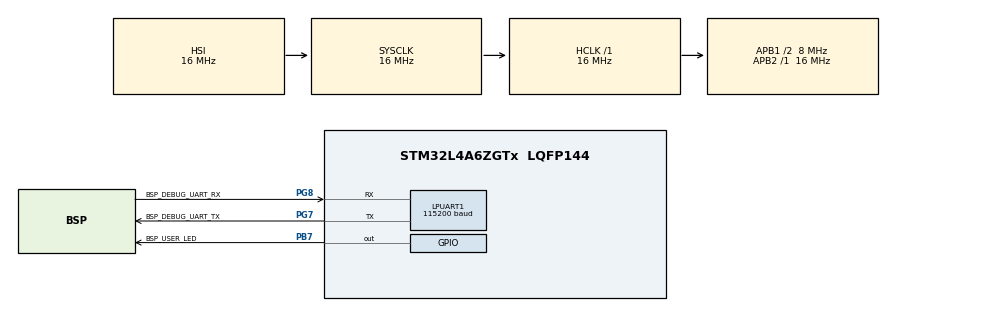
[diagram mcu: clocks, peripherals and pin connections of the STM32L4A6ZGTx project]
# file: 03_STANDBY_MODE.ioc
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LPUART1.BaudRate=115200
LPUART1.WordLength=UART_WORDLENGTH_8B
Mcu.Family=STM32L4
Mcu.Name=STM32L4A6ZGTx
Mcu.Package=LQFP144
NVIC.PriorityGroup=NVIC_PRIORITYGROUP_4
PB7.GPIO_Label=BSP_USER_LED
PB7.Signal=GPIO_Output
PC13.Mode=SYS_WakeUp1
PC13.Signal=SYS_WKUP2
PG7.GPIO_Label=BSP_DEBUG_UART_TX
PG7.Mode=Asynchronous
PG7.Signal=LPUART1_TX
PG8.GPIO_Label=BSP_DEBUG_UART_RX
PG8.Mode=Asynchronous
PG8.Signal=LPUART1_RX
ProjectManager.HeapSize=0x200
ProjectManager.StackSize=0x400
ProjectManager.TargetToolchain=STM32CubeIDE
RCC.ADCFreq_Value=192000000
RCC.AHBFreq_Value=16000000
RCC.APB1CLKDivider=RCC_HCLK_DIV2
RCC.APB1Freq_Value=8000000
RCC.APB1TimFreq_Value=16000000
RCC.APB2Freq_Value=16000000
RCC.APB2TimFreq_Value=16000000
RCC.CortexFreq_Value=16000000
RCC.HCLKFreq_Value=16000000
RCC.HSE_VALUE=8000000
RCC.HSI48_VALUE=48000000
RCC.HSI_VALUE=16000000
RCC.LSE_VALUE=32768
RCC.MSIClockRange=RCC_MSIRANGE_11
RCC.MSI_VALUE=48000000
RCC.SYSCLKFreq_VALUE=16000000
RCC.SYSCLKSource=RCC_SYSCLKSOURCE_HSI
RCC.USBFreq_Value=192000000
RCC.VCOOutputFreq_Value=384000000
board=NUCLEO-L4A6ZG

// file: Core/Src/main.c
/* USER CODE BEGIN Header */
/**
  ******************************************************************************
  * @file           : main.c
  * @brief          : Main program body
  ******************************************************************************
  * @attention
  *
  * Copyright (c) 2024 STMicroelectronics.
  * All rights reserved.
  *
  * This software is licensed under terms that can be found in the LICENSE file
  * in the root directory of this software component.
  * If no LICENSE file comes with this software, it is provided AS-IS.
  *
  ******************************************************************************
  */
/* USER CODE END Header */
#include "main.h"

/* USER CODE BEGIN Includes */
#include "stdio.h"
/* USER CODE END Includes */

UART_HandleTypeDef hlpuart1;

void SystemClock_Config(void);
static void MX_GPIO_Init(void);
static void MX_LPUART1_UART_Init(void);

int main(void)
{

  /* MCU Configuration--------------------------------------------------------*/

  /* Reset of all peripherals, Initializes the Flash interface and the Systick. */
  HAL_Init();

  /* Configure the system clock */
  SystemClock_Config();

  /* Initialize all configured peripherals */
  MX_GPIO_Init();
  MX_LPUART1_UART_Init();
  /* USER CODE BEGIN 2 */

  /*** chek if the sb flag is set ***/
	if (__HAL_PWR_GET_FLAG(PWR_FLAG_SB) != RESET)
	{
		__HAL_PWR_CLEAR_FLAG(PWR_FLAG_SB);		//clear the flag

		/*** display the string ***/
		printf("Wake up from Standby Mode\r\n");

		/*** blink the led ***/
		for (int i = 0; i < 20; i++)
		{
			HAL_GPIO_TogglePin(BSP_USER_LED_GPIO_Port, BSP_USER_LED_Pin);
			HAL_Delay(100);
		}

		/*** disable the wakeup pin ***/
		HAL_PWR_DisableWakeUpPin(PWR_WAKEUP_PIN2);	//disable PC13

		/** Deactivate RTC Wakeup **/
//		HAL_RTCEx_DeactivateWakeUpTimer(&hrtc);
	}

  /*** Now Enter the Standby Mode ***/
	/*** clear the WU FLAG ***/
	__HAL_PWR_CLEAR_FLAG(PWR_FLAG_WU);

	/** clear RTC Wake up (WU) flag **/
//	__HAL_RTC_WAKEUPTIMER_CLEAR_FLAG(&hrtc,RTC_FLAG_WUTF);

	/*** display the string ***/
	printf("Entering into Standby Mode\r\n");

	/*** blink the led ***/
	for (int i = 0; i < 5; i++)
	{
		HAL_GPIO_TogglePin(BSP_USER_LED_GPIO_Port, BSP_USER_LED_Pin);
		HAL_Delay(750);
	}

	/*** Enable the wakeu up pin ***/
	HAL_PWR_EnableWakeUpPin(PWR_WAKEUP_PIN2_HIGH);

	/** enable the RTC wake up **/

	  /*## Configure the Wake up timer ###########################################*/
	  /*  RTC Wake-up Interrupt Generation:
	      Wake-up Time Base = (RTC_WAKEUPCLOCK_RTCCLK_DIV /(LSI))
	      ==> WakeUpCounter = Wake-up Time / Wake-up Time Base

	      To configure the wake up timer to 20s the WakeUpCounter is set to 0xA017:
	      for 10s ==> WakeUpCounter = 0x4E20
	      for 5s  ==> WakeUpCounter = 0x2710
	        RTC_WAKEUPCLOCK_RTCCLK_DIV = RTCCLK_Div16 = 16
	        Wake-up Time Base = 16 /(32KHz) = 0.0005 seconds
	        ==> WakeUpCounter = ~20s/0.0005s = 40000 = 0xA017
	        ==> WakeUpCounter = ~10s/0.0005s = 20000 = 0x4E20
	        ==> WakeUpCounter = ~5s/0.0005s = 10000 = 0x2710 */

//	  if (HAL_RTCEx_SetWakeUpTimer_IT(&hrtc, 0xA017, RTC_WAKEUPCLOCK_RTCCLK_DIV16) != HAL_OK)
//	  {
//	    Error_Handler();
//	  }

	/*** Standby Mode ***/
	printf("Standby Mode is ON\r\n");

	/*** Enter the standby mode ***/
	HAL_PWR_EnterSTANDBYMode();

  /* USER CODE END 2 */

  /* Infinite loop */
  while (1)
  {

  }
}

void SystemClock_Config(void)
{
  RCC_OscInitTypeDef RCC_OscInitStruct = {0};
  RCC_ClkInitTypeDef RCC_ClkInitStruct = {0};

  /** Configure the main internal regulator output voltage
  */
  if (HAL_PWREx_ControlVoltageScaling(PWR_REGULATOR_VOLTAGE_SCALE1) != HAL_OK)
  {
    Error_Handler();
  }

  /** Initializes the RCC Oscillators according to the specified parameters
  * in the RCC_OscInitTypeDef structure.
  */
  RCC_OscInitStruct.OscillatorType = RCC_OSCILLATORTYPE_HSI;
  RCC_OscInitStruct.HSIState = RCC_HSI_ON;
  RCC_OscInitStruct.HSICalibrationValue = RCC_HSICALIBRATION_DEFAULT;
  RCC_OscInitStruct.PLL.PLLState = RCC_PLL_NONE;
  if (HAL_RCC_OscConfig(&RCC_OscInitStruct) != HAL_OK)
  {
    Error_Handler();
  }

  /** Initializes the CPU, AHB and APB buses clocks
  */
  RCC_ClkInitStruct.ClockType = RCC_CLOCKTYPE_HCLK|RCC_CLOCKTYPE_SYSCLK
                              |RCC_CLOCKTYPE_PCLK1|RCC_CLOCKTYPE_PCLK2;
  RCC_ClkInitStruct.SYSCLKSource = RCC_SYSCLKSOURCE_HSI;
  RCC_ClkInitStruct.AHBCLKDivider = RCC_SYSCLK_DIV1;
  RCC_ClkInitStruct.APB1CLKDivider = RCC_HCLK_DIV2;
  RCC_ClkInitStruct.APB2CLKDivider = RCC_HCLK_DIV1;

  if (HAL_RCC_ClockConfig(&RCC_ClkInitStruct, FLASH_LATENCY_0) != HAL_OK)
  {
    Error_Handler();
  }
}

static void MX_LPUART1_UART_Init(void)
{

  hlpuart1.Instance = LPUART1;
  hlpuart1.Init.BaudRate = 115200;
  hlpuart1.Init.WordLength = UART_WORDLENGTH_8B;
  hlpuart1.Init.StopBits = UART_STOPBITS_1;
  hlpuart1.Init.Parity = UART_PARITY_NONE;
  hlpuart1.Init.Mode = UART_MODE_TX_RX;
  hlpuart1.Init.HwFlowCtl = UART_HWCONTROL_NONE;
  hlpuart1.Init.OneBitSampling = UART_ONE_BIT_SAMPLE_DISABLE;
  hlpuart1.AdvancedInit.AdvFeatureInit = UART_ADVFEATURE_NO_INIT;
  if (HAL_UART_Init(&hlpuart1) != HAL_OK)
  {
    Error_Handler();
  }

}

static void MX_GPIO_Init(void)
{
  GPIO_InitTypeDef GPIO_InitStruct = {0};

  /* GPIO Ports Clock Enable */
  __HAL_RCC_GPIOC_CLK_ENABLE();
  __HAL_RCC_GPIOG_CLK_ENABLE();
  HAL_PWREx_EnableVddIO2();
  __HAL_RCC_GPIOB_CLK_ENABLE();

  /*Configure GPIO pin Output Level */
  HAL_GPIO_WritePin(BSP_USER_LED_GPIO_Port, BSP_USER_LED_Pin, GPIO_PIN_RESET);

  /*Configure GPIO pin : BSP_USER_LED_Pin */
  GPIO_InitStruct.Pin = BSP_USER_LED_Pin;
  GPIO_InitStruct.Mode = GPIO_MODE_OUTPUT_PP;
  GPIO_InitStruct.Pull = GPIO_NOPULL;
  GPIO_InitStruct.Speed = GPIO_SPEED_FREQ_LOW;
  HAL_GPIO_Init(BSP_USER_LED_GPIO_Port, &GPIO_InitStruct);

}

void Error_Handler(void)
{
  __disable_irq();
  while (1)
  {
  }
}
